VERSION ""

NS_ :

BS_:

BU_: DBC2
VAL_TABLE_ DBC2_Table 65535 "SNA" ;

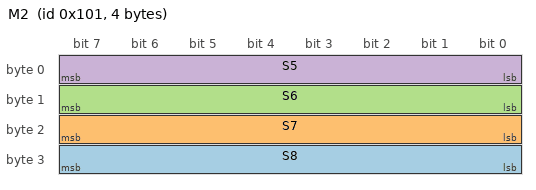
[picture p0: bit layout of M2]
BO_ 257 M2: 4 Vector__XXX
 SG_ S8 : 24|8@1- (1,0) [0|0] "" Vector__XXX
 SG_ S7 : 16|8@1- (1,0) [0|0] "" Vector__XXX
 SG_ S6 : 8|8@1- (1,0) [0|0] "" Vector__XXX
 SG_ S5 : 0|8@1- (1,0) [0|0] "" Vector__XXX

BA_DEF_  "BusType" STRING ;
BA_DEF_DEF_  "BusType" "CAN";
